# MDR1986VE1_EEPROM register map
Vendor: Milandr.; Series: ARMCM1; File version: 1.6
ARM 32-bit Cortex-M1 Microcontroller based device, CPU clock up to 144MHz, etc.
CPU: CM1 r1p0, little endian, no MPU, no FPU, 2 interrupt priority bits
Registers are 32-bit, read-write, reset 0x0 unless marked. A register's access mark holds for its fields unless they carry their own. Offsets are from the block's base; lines under a group give offsets from that group; [hi:lo] are bit positions; {n}, {i} and the like mark numbered series; 'fields as' and 'values as' point back to an identical list; <NAME> marks a mode.

## Memory map
0x40018000 MDR_EEPROM size 0x14 — EEPROM Control

## MDR_EEPROM — EEPROM Control
Base 0x40018000
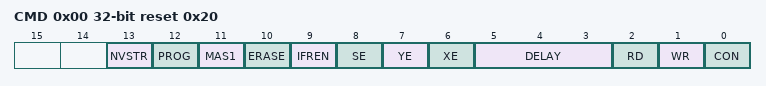
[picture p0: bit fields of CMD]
0x00 CMD reset 0x20 (reset mask 0x3FF) — EEPROM Control register
  [13] NVSTR — Memory access mode
    0=Read mode; 1=Write (Programming or erase mode)
  [12] PROG — Programm EEPROM_DI to ADDR[16:0]
    0=Inactive (No programm operation); 1=Active (Programm operation)
  [11] MAS1 — Erase whole block with ERASE
    0=Off (Disable); 1=On (Enable)
  [10] ERASE — Erase string at ADDR[16:0]
    0=Inactive (No erase operation); 1=Active (Erase operation)
  [9] IFREN — Select main or info memory
    0=Main memory; 1=Info memory
  [8] SE — RD Amplifier enable
    0=Off (Disable); 1=On (Enable)
  [7] YE — Enable ADDR[8..2]
    0=Off (Disable); 1=On (Enable)
  [6] XE — Enable ADDR[16..9]
    0=Off (Disable); 1=On (Enable)
  [5:3] DELAY — Memory access CPU delay tacts
    0=le25MHz (CPU freq is up to 25MHz); 1=le50MHz (CPU freq is up to 50MHz); 2=le75MHz (CPU freq is up to 75MHz); 3=le100MHz (CPU freq is up to 100MHz); 4=le125MHz (CPU freq is up to 125MHz); 5=le150MHz (CPU freq is up to 150MHz); 6=le175MHz (CPU freq is up to 175MHz); 7=le200MHz (CPU freq is up to 200MHz)
  [2] RD — Read operation
    0=Inactive (No read operation); 1=Active (Read operation)
  [1] WR — Write operation
    0=Inactive (No write operation); 1=Active (Write operation)
  [0] CON — Enable memory access through EEPROM controller
    0=Normal access to memory; 1=Controller Access (Access to memory though registers)
0x04 ADDR — Address register
0x08 DI — Write data register
0x0C DO — Read data register
0x10 KEY — Unlock block register
